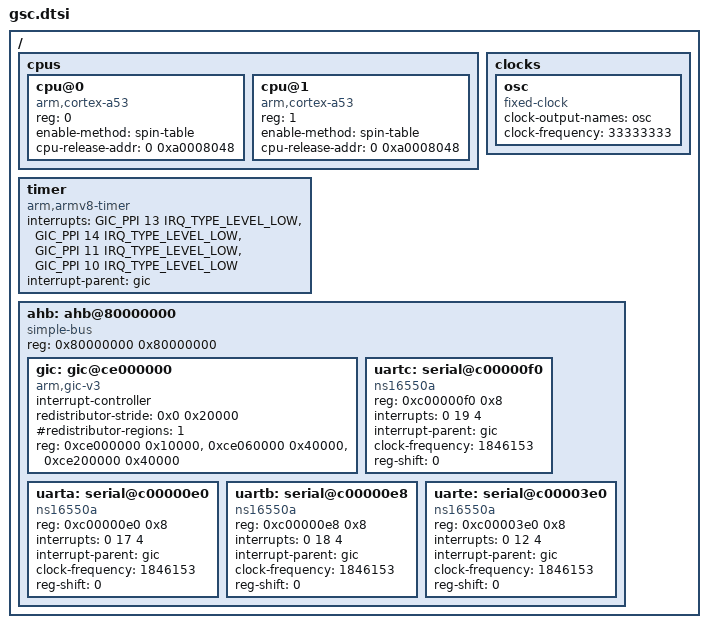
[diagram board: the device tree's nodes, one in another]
// SPDX-License-Identifier: GPL-2.0
/*
 * Device Tree file for HPE GSC
 */

#include <dt-bindings/interrupt-controller/arm-gic.h>

/ {
	#address-cells = <1>;
	#size-cells = <1>;

	cpus {
		#address-cells = <1>;
		#size-cells = <0>;

		cpu@0 {
			device_type = "cpu";
			compatible = "arm,cortex-a53";
			reg = <0>;
			enable-method = "spin-table";
			cpu-release-addr = <0 0xa0008048>;
		};

		cpu@1 {
			device_type = "cpu";
			compatible = "arm,cortex-a53";
			reg = <1>;
			enable-method = "spin-table";
			cpu-release-addr = <0 0xa0008048>;
		};
	};

	clocks {
		osc: osc {
			compatible = "fixed-clock";
			#clock-cells = <0>;
			clock-output-names = "osc";
			clock-frequency = <33333333>;
		};
	};

	timer {
		compatible = "arm,armv8-timer";
		interrupts = <GIC_PPI 13 IRQ_TYPE_LEVEL_LOW>,
			     <GIC_PPI 14 IRQ_TYPE_LEVEL_LOW>,
			     <GIC_PPI 11 IRQ_TYPE_LEVEL_LOW>,
			     <GIC_PPI 10 IRQ_TYPE_LEVEL_LOW>;
		interrupt-parent = <&gic>;
	};

	ahb: ahb@80000000 {
		compatible = "simple-bus";
		#address-cells = <1>;
		#size-cells = <1>;
		reg = <0x80000000 0x80000000>;
		ranges;

		gic: gic@ce000000 {
			compatible = "arm,gic-v3";
			#interrupt-cells = <3>;
			#address-cells = <0>;
			interrupt-controller;
			redistributor-stride = <0x0 0x20000>;
			#redistributor-regions = <1>;
			reg = <0xce000000 0x10000>,
			      <0xce060000 0x40000>,
			      <0xce200000 0x40000>;
		};

		uartc: serial@c00000f0 {
			compatible = "ns16550a";
			reg = <0xc00000f0 0x8>;
			interrupts = <0 19 4>;
			interrupt-parent = <&gic>;
			clock-frequency = <1846153>;
			reg-shift = <0>;
		};

		uarta: serial@c00000e0 {
			compatible = "ns16550a";
			reg = <0xc00000e0 0x8>;
			interrupts = <0 17 4>;
			interrupt-parent = <&gic>;
			clock-frequency = <1846153>;
			reg-shift = <0>;
		};

		uartb: serial@c00000e8 {
			compatible = "ns16550a";
			reg = <0xc00000e8 0x8>;
			interrupts = <0 18 4>;
			interrupt-parent = <&gic>;
			clock-frequency = <1846153>;
			reg-shift = <0>;
		};

		uarte: serial@c00003e0 {
			compatible = "ns16550a";
			reg = <0xc00003e0 0x8>;
			interrupts = <0 12 4>;
			interrupt-parent = <&gic>;
			clock-frequency = <1846153>;
			reg-shift = <0>;
		};
	};
};
